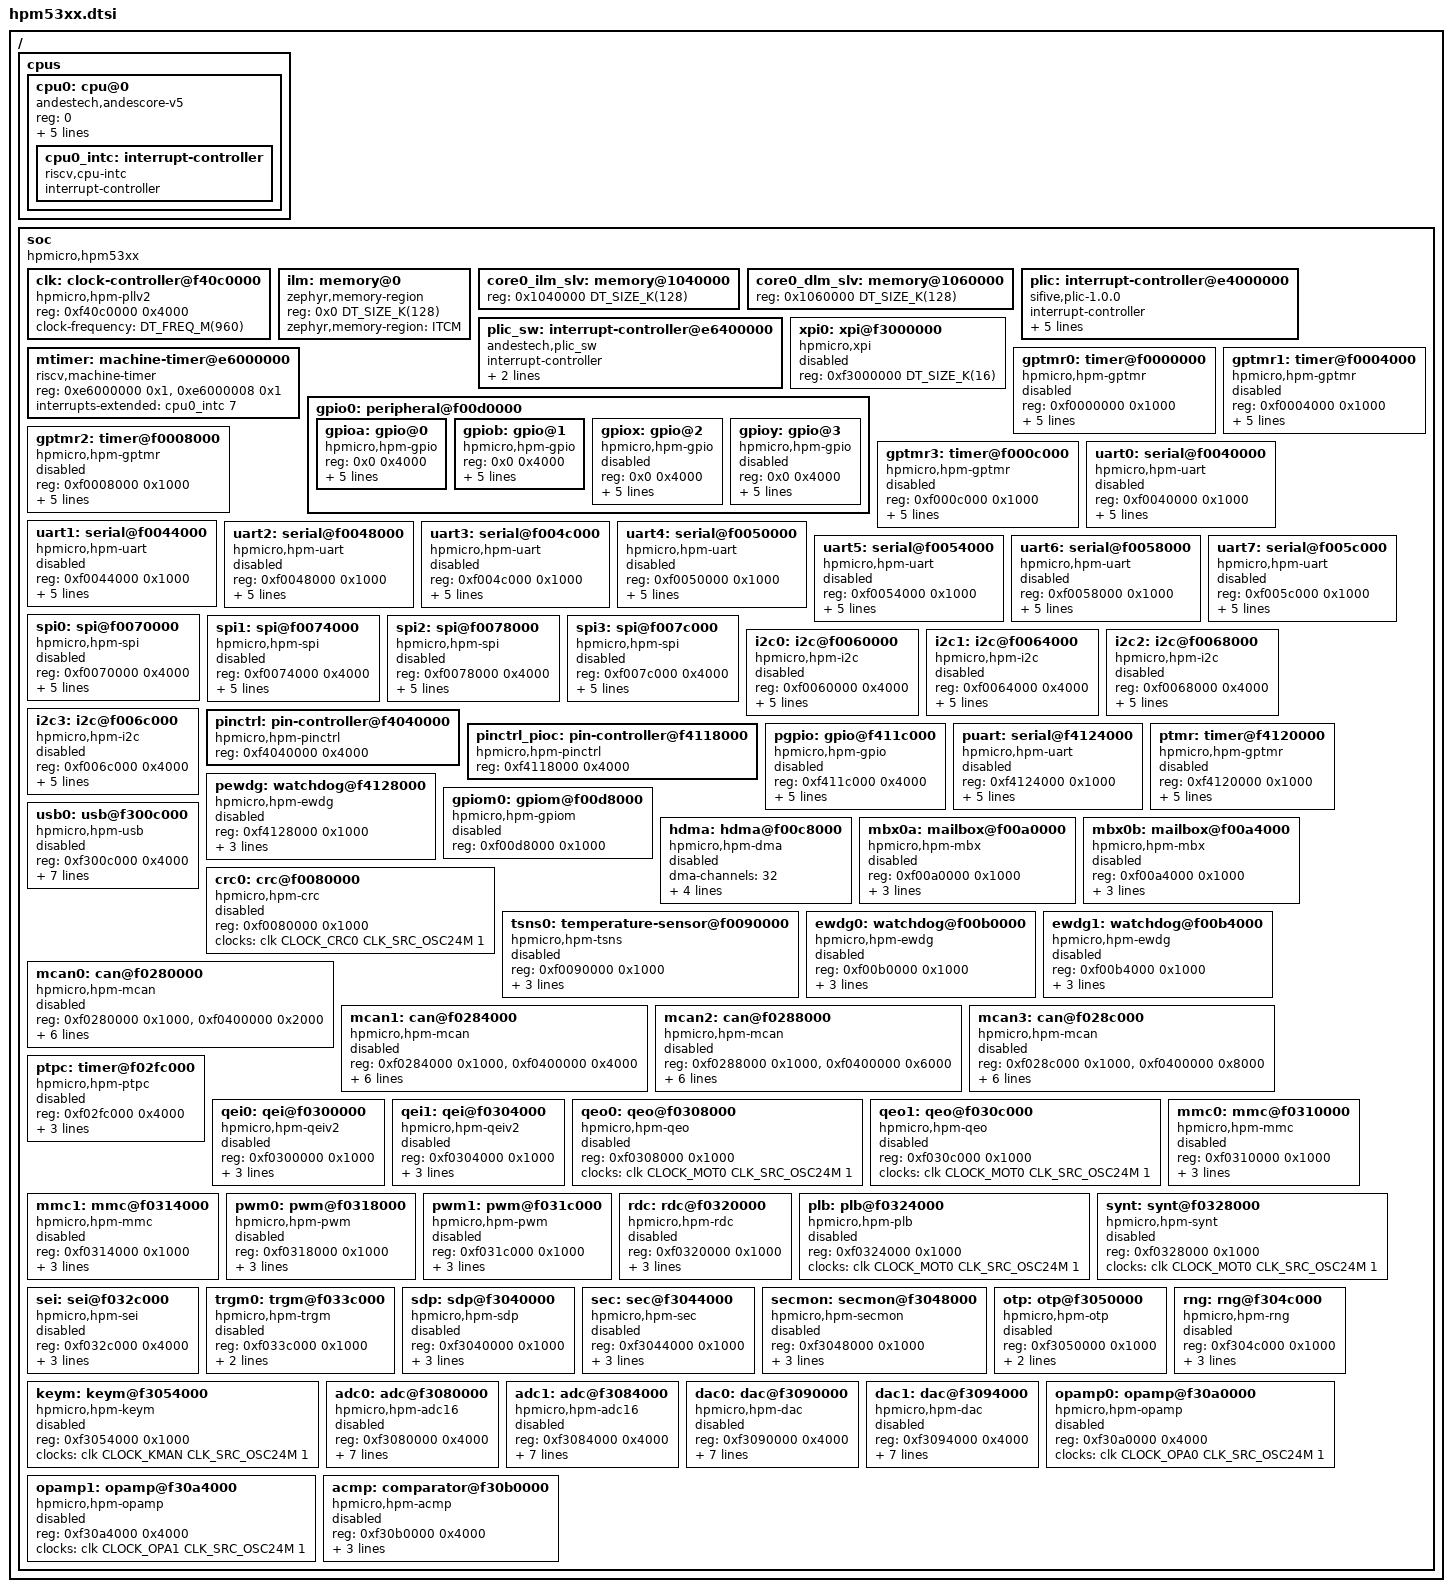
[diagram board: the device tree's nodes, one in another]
/*
 * Copyright (c) 2024-2026 HPMicro
 * SPDX-License-Identifier: Apache-2.0
 */

/dts-v1/;
#include <zephyr/dt-bindings/gpio/gpio.h>
#include <mem.h>
#include <freq.h>

/ {
	#address-cells = <1>;
	#size-cells = <1>;

	cpus {
		#address-cells = <1>;
		#size-cells = <0>;

		cpu0: cpu@0 {
			compatible = "andestech,andescore-v5", "riscv";
			reg = <0>;
			status = "okay";
			riscv,isa-base = "rv32i";
			riscv,isa-extensions = "i", "m", "a", "c", "zicsr", "zifencei";
			i-cache-line-size = <32>;
			d-cache-line-size = <32>;

			cpu0_intc: interrupt-controller {
				compatible = "riscv,cpu-intc";
				#address-cells = <0>;
				#interrupt-cells = <1>;
				interrupt-controller;
			};
		};
	};

	soc {
		#address-cells = <1>;
		#size-cells = <1>;
		compatible = "hpmicro,hpm53xx";
		ranges;

		clk: clock-controller@f40c0000 {
			compatible = "hpmicro,hpm-pllv2";
			reg = <0xf40c0000 0x4000>;
			clock-frequency = <DT_FREQ_M(960)>;
			reg-names = "clk";
			#clock-cells = <3>;
			status = "okay";
		};

		ilm: memory@0 {
			compatible = "zephyr,memory-region";
			reg = <0x0 DT_SIZE_K(128)>;
			zephyr,memory-region = "ITCM";
		};

		core0_ilm_slv: memory@1040000 {
			reg = <0x1040000 DT_SIZE_K(128)>;
		};

		core0_dlm_slv: memory@1060000 {
			reg = <0x1060000 DT_SIZE_K(128)>;
		};

		plic: interrupt-controller@e4000000 {
			compatible = "sifive,plic-1.0.0";
			#address-cells = <1>;
			#interrupt-cells = <2>;
			interrupt-controller;
			reg = <0xe4000000 0x1000>,
			      <0xe4002000 0x800>,
			      <0xe4200000 0x10000>;
			reg-names = "prio", "irq_en", "reg";
			riscv,max-priority = <31>;
			riscv,ndev = <127>;
			interrupts-extended = <&cpu0_intc 11>;
		};

		plic_sw: interrupt-controller@e6400000 {
			compatible = "andestech,plic_sw";
			#address-cells = <1>;
			#interrupt-cells = <2>;
			interrupt-controller;
			reg = <0xe6400000 0x400000>;
			interrupts-extended = <&cpu0_intc 3>;
		};

		mtimer: machine-timer@e6000000 {
			compatible = "riscv,machine-timer";
			reg = <0xe6000000 0x1>,
			      <0xe6000008 0x1>;
			reg-names = "mtime", "mtimecmp";
			interrupts-extended = <&cpu0_intc 7>;
		};

		xpi0: xpi@f3000000 {
			compatible = "hpmicro,xpi";
			reg = <0xf3000000 DT_SIZE_K(16)>;
			#address-cells = <1>;
			#size-cells = <1>;
			status = "disabled";
		};

		gpio0: peripheral@f00d0000 {
			#address-cells = <1>;
			#size-cells = <1>;
			ranges = <0x0 0xf00d0000 DT_SIZE_K(16)>;
		};

		gptmr0: timer@f0000000 {
			compatible = "hpmicro,hpm-gptmr";
			reg = <0xf0000000 0x1000>;
			interrupts = <5 1>;
			interrupt-parent = <&plic>;
			clocks = <&clk CLOCK_GPTMR0 CLK_SRC_OSC24M 1>;
			clock-names = "gptmr";
			clock-name = <CLOCK_GPTMR0>;
			clock-src = <CLK_SRC_OSC24M>;
			status = "disabled";
		};

		gptmr1: timer@f0004000 {
			compatible = "hpmicro,hpm-gptmr";
			reg = <0xf0004000 0x1000>;
			interrupts = <6 1>;
			interrupt-parent = <&plic>;
			clocks = <&clk CLOCK_GPTMR1 CLK_SRC_OSC24M 1>;
			clock-names = "gptmr";
			clock-name = <CLOCK_GPTMR1>;
			clock-src = <CLK_SRC_OSC24M>;
			status = "disabled";
		};

		gptmr2: timer@f0008000 {
			compatible = "hpmicro,hpm-gptmr";
			reg = <0xf0008000 0x1000>;
			interrupts = <7 1>;
			interrupt-parent = <&plic>;
			clocks = <&clk CLOCK_GPTMR2 CLK_SRC_OSC24M 1>;
			clock-names = "gptmr";
			clock-name = <CLOCK_GPTMR2>;
			clock-src = <CLK_SRC_OSC24M>;
			status = "disabled";
		};

		gptmr3: timer@f000c000 {
			compatible = "hpmicro,hpm-gptmr";
			reg = <0xf000c000 0x1000>;
			interrupts = <8 1>;
			interrupt-parent = <&plic>;
			clocks = <&clk CLOCK_GPTMR3 CLK_SRC_OSC24M 1>;
			clock-names = "gptmr";
			clock-name = <CLOCK_GPTMR3>;
			clock-src = <CLK_SRC_OSC24M>;
			status = "disabled";
		};

		uart0: serial@f0040000 {
			compatible = "hpmicro,hpm-uart";
			reg = <0xf0040000 0x1000>;
			interrupts = <13 1>;
			interrupt-names = "uart";
			clocks = <&clk CLOCK_UART0 CLK_SRC_OSC24M 1>;
			clock-names = "uart";
			clock-name = <CLOCK_UART0>;
			clock-src = <CLK_SRC_OSC24M>;
			interrupt-parent = <&plic>;
			status = "disabled";
		};

		uart1: serial@f0044000 {
			compatible = "hpmicro,hpm-uart";
			reg = <0xf0044000 0x1000>;
			interrupts = <14 1>;
			interrupt-names = "uart";
			clocks = <&clk CLOCK_UART1 CLK_SRC_OSC24M 1>;
			clock-names = "uart";
			clock-name = <CLOCK_UART1>;
			clock-src = <CLK_SRC_OSC24M>;
			interrupt-parent = <&plic>;
			status = "disabled";
		};

		uart2: serial@f0048000 {
			compatible = "hpmicro,hpm-uart";
			reg = <0xf0048000 0x1000>;
			interrupts = <15 1>;
			interrupt-names = "uart";
			clocks = <&clk CLOCK_UART2 CLK_SRC_OSC24M 1>;
			clock-names = "uart";
			clock-name = <CLOCK_UART2>;
			clock-src = <CLK_SRC_OSC24M>;
			interrupt-parent = <&plic>;
			status = "disabled";
		};

		uart3: serial@f004c000 {
			compatible = "hpmicro,hpm-uart";
			reg = <0xf004c000 0x1000>;
			interrupts = <16 1>;
			interrupt-names = "uart";
			clocks = <&clk CLOCK_UART3 CLK_SRC_OSC24M 1>;
			clock-names = "uart";
			clock-name = <CLOCK_UART3>;
			clock-src = <CLK_SRC_OSC24M>;
			interrupt-parent = <&plic>;
			status = "disabled";
		};

		uart4: serial@f0050000 {
			compatible = "hpmicro,hpm-uart";
			reg = <0xf0050000 0x1000>;
			interrupts = <17 1>;
			interrupt-names = "uart";
			clocks = <&clk CLOCK_UART4 CLK_SRC_OSC24M 1>;
			clock-names = "uart";
			clock-name = <CLOCK_UART4>;
			clock-src = <CLK_SRC_OSC24M>;
			interrupt-parent = <&plic>;
			status = "disabled";
		};

		uart5: serial@f0054000 {
			compatible = "hpmicro,hpm-uart";
			reg = <0xf0054000 0x1000>;
			interrupts = <18 1>;
			interrupt-names = "uart";
			clocks = <&clk CLOCK_UART5 CLK_SRC_OSC24M 1>;
			clock-names = "uart";
			clock-name = <CLOCK_UART5>;
			clock-src = <CLK_SRC_OSC24M>;
			interrupt-parent = <&plic>;
			status = "disabled";
		};

		uart6: serial@f0058000 {
			compatible = "hpmicro,hpm-uart";
			reg = <0xf0058000 0x1000>;
			interrupts = <19 1>;
			interrupt-names = "uart";
			clocks = <&clk CLOCK_UART6 CLK_SRC_OSC24M 1>;
			clock-names = "uart";
			clock-name = <CLOCK_UART6>;
			clock-src = <CLK_SRC_OSC24M>;
			interrupt-parent = <&plic>;
			status = "disabled";
		};

		uart7: serial@f005c000 {
			compatible = "hpmicro,hpm-uart";
			reg = <0xf005c000 0x1000>;
			interrupts = <20 1>;
			interrupt-names = "uart";
			clocks = <&clk CLOCK_UART7 CLK_SRC_OSC24M 1>;
			clock-names = "uart";
			clock-name = <CLOCK_UART7>;
			clock-src = <CLK_SRC_OSC24M>;
			interrupt-parent = <&plic>;
			status = "disabled";
		};

		spi0: spi@f0070000 {
			compatible = "hpmicro,hpm-spi";
			reg = <0xf0070000 0x4000>;
			interrupts = <25 1>;
			interrupt-parent = <&plic>;
			clocks = <&clk CLOCK_SPI0 CLK_SRC_PLL1_CLK0 10>;
			clock-names = "spi";
			clock-name = <CLOCK_SPI0>;
			clock-src = <CLK_SRC_PLL1_CLK0>;
			#address-cells = <1>;
			#size-cells = <0>;
			status = "disabled";
		};

		spi1: spi@f0074000 {
			compatible = "hpmicro,hpm-spi";
			reg = <0xf0074000 0x4000>;
			interrupts = <26 1>;
			interrupt-parent = <&plic>;
			clocks = <&clk CLOCK_SPI1 CLK_SRC_PLL1_CLK0 10>;
			clock-names = "spi";
			clock-name = <CLOCK_SPI1>;
			clock-src = <CLK_SRC_PLL1_CLK0>;
			#address-cells = <1>;
			#size-cells = <0>;
			status = "disabled";
		};

		spi2: spi@f0078000 {
			compatible = "hpmicro,hpm-spi";
			reg = <0xf0078000 0x4000>;
			interrupts = <27 1>;
			interrupt-parent = <&plic>;
			clocks = <&clk CLOCK_SPI2 CLK_SRC_PLL1_CLK0 10>;
			clock-names = "spi";
			clock-name = <CLOCK_SPI2>;
			clock-src = <CLK_SRC_PLL1_CLK0>;
			#address-cells = <1>;
			#size-cells = <0>;
			status = "disabled";
		};

		spi3: spi@f007c000 {
			compatible = "hpmicro,hpm-spi";
			reg = <0xf007c000 0x4000>;
			interrupts = <28 1>;
			interrupt-parent = <&plic>;
			clocks = <&clk CLOCK_SPI3 CLK_SRC_PLL1_CLK0 10>;
			clock-names = "spi";
			clock-name = <CLOCK_SPI3>;
			clock-src = <CLK_SRC_PLL1_CLK0>;
			#address-cells = <1>;
			#size-cells = <0>;
			status = "disabled";
		};

		i2c0: i2c@f0060000 {
			compatible = "hpmicro,hpm-i2c";
			reg = <0xf0060000 0x4000>;
			interrupts = <21 1>;
			interrupt-parent = <&plic>;
			clocks = <&clk CLOCK_I2C0 CLK_SRC_PLL1_CLK0 10>;
			clock-names = "i2c";
			clock-name = <CLOCK_I2C0>;
			clock-src = <CLK_SRC_PLL1_CLK0>;
			#address-cells = <1>;
			#size-cells = <0>;
			status = "disabled";
		};

		i2c1: i2c@f0064000 {
			compatible = "hpmicro,hpm-i2c";
			reg = <0xf0064000 0x4000>;
			interrupts = <22 1>;
			interrupt-parent = <&plic>;
			clocks = <&clk CLOCK_I2C1 CLK_SRC_PLL1_CLK0 10>;
			clock-names = "i2c";
			clock-name = <CLOCK_I2C1>;
			clock-src = <CLK_SRC_PLL1_CLK0>;
			#address-cells = <1>;
			#size-cells = <0>;
			status = "disabled";
		};

		i2c2: i2c@f0068000 {
			compatible = "hpmicro,hpm-i2c";
			reg = <0xf0068000 0x4000>;
			interrupts = <23 1>;
			interrupt-parent = <&plic>;
			clocks = <&clk CLOCK_I2C2 CLK_SRC_PLL1_CLK0 10>;
			clock-names = "i2c";
			clock-name = <CLOCK_I2C2>;
			clock-src = <CLK_SRC_PLL1_CLK0>;
			#address-cells = <1>;
			#size-cells = <0>;
			status = "disabled";
		};

		i2c3: i2c@f006c000 {
			compatible = "hpmicro,hpm-i2c";
			reg = <0xf006c000 0x4000>;
			interrupts = <24 1>;
			interrupt-parent = <&plic>;
			clocks = <&clk CLOCK_I2C3 CLK_SRC_PLL1_CLK0 10>;
			clock-names = "i2c";
			clock-name = <CLOCK_I2C3>;
			clock-src = <CLK_SRC_PLL1_CLK0>;
			#address-cells = <1>;
			#size-cells = <0>;
			status = "disabled";
		};

		pinctrl: pin-controller@f4040000 {
			compatible = "hpmicro,hpm-pinctrl";
			reg = <0xf4040000 0x4000>;
			status = "okay";
		};

		pinctrl_pioc: pin-controller@f4118000 {
			compatible = "hpmicro,hpm-pinctrl";
			reg = <0xf4118000 0x4000>;
			status = "okay";
		};

		pgpio: gpio@f411c000 {
			compatible = "hpmicro,hpm-gpio";
			reg = <0xf411c000 0x4000>;
			ngpios = <8>;
			gpio-controller;
			#gpio-cells = <2>;
			hpmicro-gpio-port = <0>;
			interrupts = <65 1>;
			interrupt-parent = <&plic>;
			status = "disabled";
		};

		puart: serial@f4124000 {
			compatible = "hpmicro,hpm-uart";
			reg = <0xf4124000 0x1000>;
			interrupts = <67 1>;
			interrupt-names = "uart";
			interrupt-parent = <&plic>;
			clocks = <&clk CLOCK_PUART CLK_SRC_OSC24M 1>;
			clock-names = "uart";
			clock-name = <CLOCK_PUART>;
			clock-src = <CLK_SRC_OSC24M>;
			status = "disabled";
		};

		ptmr: timer@f4120000 {
			compatible = "hpmicro,hpm-gptmr";
			reg = <0xf4120000 0x1000>;
			interrupts = <66 1>;
			interrupt-parent = <&plic>;
			clocks = <&clk CLOCK_PTMR CLK_SRC_OSC24M 1>;
			clock-names = "gptmr";
			clock-name = <CLOCK_PTMR>;
			clock-src = <CLK_SRC_OSC24M>;
			status = "disabled";
		};

		pewdg: watchdog@f4128000 {
			compatible = "hpmicro,hpm-ewdg";
			reg = <0xf4128000 0x1000>;
			interrupts = <68 1>;
			interrupt-parent = <&plic>;
			clocks = <&clk CLOCK_PWDG CLK_SRC_OSC24M 1>;
			clock-names = "ewdg";
			status = "disabled";
		};

		gpiom0: gpiom@f00d8000 {
			compatible = "hpmicro,hpm-gpiom";
			reg = <0xf00d8000 0x1000>;
			status = "disabled";
		};

		hdma: hdma@f00c8000 {
			#dma-cells = <2>;
			compatible = "hpmicro,hpm-dma";
			dma-channels = <32>;
			dma-requests = <32>;
			reg = <0xf00c8000 0x4000>,
			      <0xf00c4000 0x4000>;
			interrupts = <34 1>;
			interrupt-parent = <&plic>;
			status = "disabled";
		};

		mbx0a: mailbox@f00a0000 {
			compatible = "hpmicro,hpm-mbx";
			reg = <0xf00a0000 0x1000>;
			interrupts = <30 1>;
			interrupt-parent = <&plic>;
			clocks = <&clk CLOCK_MBX0 CLK_SRC_OSC24M 1>;
			clock-names = "mbx";
			status = "disabled";
		};

		mbx0b: mailbox@f00a4000 {
			compatible = "hpmicro,hpm-mbx";
			reg = <0xf00a4000 0x1000>;
			interrupts = <31 1>;
			interrupt-parent = <&plic>;
			clocks = <&clk CLOCK_MBX0 CLK_SRC_OSC24M 1>;
			clock-names = "mbx";
			status = "disabled";
		};

		usb0: usb@f300c000 {
			compatible = "hpmicro,hpm-usb";
			reg = <0xf300c000 0x4000>;
			interrupts = <51 1>;
			interrupt-parent = <&plic>;
			clocks = <&clk CLOCK_USB0 CLK_SRC_OSC24M 1>;
			clock-names = "usb";
			clock-name = <CLOCK_USB0>;
			clock-src = <CLK_SRC_OSC24M>;
			maximum-speed = "high-speed";
			num-bidir-endpoints = <16>;
			status = "disabled";
		};

		crc0: crc@f0080000 {
			compatible = "hpmicro,hpm-crc";
			reg = <0xf0080000 0x1000>;
			clocks = <&clk CLOCK_CRC0 CLK_SRC_OSC24M 1>;
			clock-names = "crc";
			status = "disabled";
		};

		tsns0: temperature-sensor@f0090000 {
			compatible = "hpmicro,hpm-tsns";
			reg = <0xf0090000 0x1000>;
			interrupts = <29 1>;
			interrupt-parent = <&plic>;
			clocks = <&clk CLOCK_TSNS CLK_SRC_OSC24M 1>;
			clock-names = "tsns";
			status = "disabled";
		};

		ewdg0: watchdog@f00b0000 {
			compatible = "hpmicro,hpm-ewdg";
			reg = <0xf00b0000 0x1000>;
			interrupts = <32 1>;
			interrupt-parent = <&plic>;
			clocks = <&clk CLOCK_WATCHDOG0 CLK_SRC_OSC24M 1>;
			clock-names = "ewdg";
			status = "disabled";
		};

		ewdg1: watchdog@f00b4000 {
			compatible = "hpmicro,hpm-ewdg";
			reg = <0xf00b4000 0x1000>;
			interrupts = <33 1>;
			interrupt-parent = <&plic>;
			clocks = <&clk CLOCK_WATCHDOG1 CLK_SRC_OSC24M 1>;
			clock-names = "ewdg";
			status = "disabled";
		};

		/*
		 * All MCAN instances share the 32 KiB AHB SRAM at 0xF0400000.
		 * Each instance owns an 8 KiB window selected by the offset in
		 * bosch,mram-cfg. The message_ram reg range ends at each instance's
		 * window, so the generic Bosch M_CAN frontend derives an exact 8 KiB
		 * MRAM size after applying the per-instance offset.
		 */
		mcan0: can@f0280000 {
			compatible = "hpmicro,hpm-mcan";
			reg = <0xf0280000 0x1000>,
			      <0xf0400000 0x2000>;
			reg-names = "m_can", "message_ram";
			interrupts = <35 1>;
			interrupt-parent = <&plic>;
			clocks = <&clk CLOCK_CAN0 CLK_SRC_PLL1_CLK0 10>;
			clock-names = "can";
			clock-name = <CLOCK_CAN0>;
			clock-src = <CLK_SRC_PLL1_CLK0>;
			bosch,mram-cfg = <0x0 14 8 8 0 0 4 8>;
			status = "disabled";
		};

		mcan1: can@f0284000 {
			compatible = "hpmicro,hpm-mcan";
			reg = <0xf0284000 0x1000>,
			      <0xf0400000 0x4000>;
			reg-names = "m_can", "message_ram";
			interrupts = <36 1>;
			interrupt-parent = <&plic>;
			clocks = <&clk CLOCK_CAN1 CLK_SRC_PLL1_CLK0 10>;
			clock-names = "can";
			clock-name = <CLOCK_CAN1>;
			clock-src = <CLK_SRC_PLL1_CLK0>;
			bosch,mram-cfg = <0x2000 14 8 8 0 0 4 8>;
			status = "disabled";
		};

		mcan2: can@f0288000 {
			compatible = "hpmicro,hpm-mcan";
			reg = <0xf0288000 0x1000>,
			      <0xf0400000 0x6000>;
			reg-names = "m_can", "message_ram";
			interrupts = <37 1>;
			interrupt-parent = <&plic>;
			clocks = <&clk CLOCK_CAN2 CLK_SRC_PLL1_CLK0 10>;
			clock-names = "can";
			clock-name = <CLOCK_CAN2>;
			clock-src = <CLK_SRC_PLL1_CLK0>;
			bosch,mram-cfg = <0x4000 14 8 8 0 0 4 8>;
			status = "disabled";
		};

		mcan3: can@f028c000 {
			compatible = "hpmicro,hpm-mcan";
			reg = <0xf028c000 0x1000>,
			      <0xf0400000 0x8000>;
			reg-names = "m_can", "message_ram";
			interrupts = <38 1>;
			interrupt-parent = <&plic>;
			clocks = <&clk CLOCK_CAN3 CLK_SRC_PLL1_CLK0 10>;
			clock-names = "can";
			clock-name = <CLOCK_CAN3>;
			clock-src = <CLK_SRC_PLL1_CLK0>;
			bosch,mram-cfg = <0x6000 14 8 8 0 0 4 8>;
			status = "disabled";
		};

		ptpc: timer@f02fc000 {
			compatible = "hpmicro,hpm-ptpc";
			reg = <0xf02fc000 0x4000>;
			interrupts = <39 1>;
			interrupt-parent = <&plic>;
			clocks = <&clk CLOCK_PTPC CLK_SRC_OSC24M 1>;
			clock-names = "ptpc";
			status = "disabled";
		};

		qei0: qei@f0300000 {
			compatible = "hpmicro,hpm-qeiv2";
			reg = <0xf0300000 0x1000>;
			interrupts = <41 1>;
			interrupt-parent = <&plic>;
			clocks = <&clk CLOCK_MOT0 CLK_SRC_OSC24M 1>;
			clock-names = "qei";
			status = "disabled";
		};

		qei1: qei@f0304000 {
			compatible = "hpmicro,hpm-qeiv2";
			reg = <0xf0304000 0x1000>;
			interrupts = <46 1>;
			interrupt-parent = <&plic>;
			clocks = <&clk CLOCK_MOT0 CLK_SRC_OSC24M 1>;
			clock-names = "qei";
			status = "disabled";
		};

		qeo0: qeo@f0308000 {
			compatible = "hpmicro,hpm-qeo";
			reg = <0xf0308000 0x1000>;
			clocks = <&clk CLOCK_MOT0 CLK_SRC_OSC24M 1>;
			clock-names = "qeo";
			status = "disabled";
		};

		qeo1: qeo@f030c000 {
			compatible = "hpmicro,hpm-qeo";
			reg = <0xf030c000 0x1000>;
			clocks = <&clk CLOCK_MOT0 CLK_SRC_OSC24M 1>;
			clock-names = "qeo";
			status = "disabled";
		};

		mmc0: mmc@f0310000 {
			compatible = "hpmicro,hpm-mmc";
			reg = <0xf0310000 0x1000>;
			interrupts = <43 1>;
			interrupt-parent = <&plic>;
			clocks = <&clk CLOCK_MOT0 CLK_SRC_OSC24M 1>;
			clock-names = "mmc";
			status = "disabled";
		};

		mmc1: mmc@f0314000 {
			compatible = "hpmicro,hpm-mmc";
			reg = <0xf0314000 0x1000>;
			interrupts = <48 1>;
			interrupt-parent = <&plic>;
			clocks = <&clk CLOCK_MOT0 CLK_SRC_OSC24M 1>;
			clock-names = "mmc";
			status = "disabled";
		};

		pwm0: pwm@f0318000 {
			compatible = "hpmicro,hpm-pwm";
			reg = <0xf0318000 0x1000>;
			interrupts = <40 1>;
			interrupt-parent = <&plic>;
			clocks = <&clk CLOCK_MOT0 CLK_SRC_OSC24M 1>;
			clock-names = "pwm";
			#pwm-cells = <3>;
			status = "disabled";
		};

		pwm1: pwm@f031c000 {
			compatible = "hpmicro,hpm-pwm";
			reg = <0xf031c000 0x1000>;
			interrupts = <45 1>;
			interrupt-parent = <&plic>;
			clocks = <&clk CLOCK_MOT0 CLK_SRC_OSC24M 1>;
			clock-names = "pwm";
			#pwm-cells = <3>;
			status = "disabled";
		};

		rdc: rdc@f0320000 {
			compatible = "hpmicro,hpm-rdc";
			reg = <0xf0320000 0x1000>;
			interrupts = <50 1>;
			interrupt-parent = <&plic>;
			clocks = <&clk CLOCK_MOT0 CLK_SRC_OSC24M 1>;
			clock-names = "rdc";
			status = "disabled";
		};

		plb: plb@f0324000 {
			compatible = "hpmicro,hpm-plb";
			reg = <0xf0324000 0x1000>;
			clocks = <&clk CLOCK_MOT0 CLK_SRC_OSC24M 1>;
			clock-names = "plb";
			status = "disabled";
		};

		synt: synt@f0328000 {
			compatible = "hpmicro,hpm-synt";
			reg = <0xf0328000 0x1000>;
			clocks = <&clk CLOCK_MOT0 CLK_SRC_OSC24M 1>;
			clock-names = "synt";
			status = "disabled";
		};

		sei: sei@f032c000 {
			compatible = "hpmicro,hpm-sei";
			reg = <0xf032c000 0x4000>;
			interrupts = <42 1>, <47 1>;
			interrupt-parent = <&plic>;
			clocks = <&clk CLOCK_MOT0 CLK_SRC_OSC24M 1>;
			clock-names = "sei";
			status = "disabled";
		};

		trgm0: trgm@f033c000 {
			compatible = "hpmicro,hpm-trgm";
			reg = <0xf033c000 0x1000>;
			interrupts = <44 1>, <49 1>;
			interrupt-parent = <&plic>;
			status = "disabled";
		};

		sdp: sdp@f3040000 {
			compatible = "hpmicro,hpm-sdp";
			reg = <0xf3040000 0x1000>;
			interrupts = <53 1>;
			interrupt-parent = <&plic>;
			clocks = <&clk CLOCK_SDP CLK_SRC_OSC24M 1>;
			clock-names = "sdp";
			status = "disabled";
		};

		sec: sec@f3044000 {
			compatible = "hpmicro,hpm-sec";
			reg = <0xf3044000 0x1000>;
			interrupts = <54 1>;
			interrupt-parent = <&plic>;
			clocks = <&clk CLOCK_SDP CLK_SRC_OSC24M 1>;
			clock-names = "sec";
			status = "disabled";
		};

		secmon: secmon@f3048000 {
			compatible = "hpmicro,hpm-secmon";
			reg = <0xf3048000 0x1000>;
			interrupts = <55 1>;
			interrupt-parent = <&plic>;
			clocks = <&clk CLOCK_SDP CLK_SRC_OSC24M 1>;
			clock-names = "secmon";
			status = "disabled";
		};

		otp: otp@f3050000 {
			compatible = "hpmicro,hpm-otp";
			reg = <0xf3050000 0x1000>;
			interrupts = <57 1>;
			interrupt-parent = <&plic>;
			status = "disabled";
		};

		keym: keym@f3054000 {
			compatible = "hpmicro,hpm-keym";
			reg = <0xf3054000 0x1000>;
			clocks = <&clk CLOCK_KMAN CLK_SRC_OSC24M 1>;
			clock-names = "keym";
			status = "disabled";
		};

		rng: rng@f304c000 {
			compatible = "hpmicro,hpm-rng";
			reg = <0xf304c000 0x1000>;
			interrupts = <56 1>;
			interrupt-parent = <&plic>;
			clocks = <&clk CLOCK_RNG CLK_SRC_OSC24M 1>;
			clock-names = "rng";
			status = "disabled";
		};

		adc0: adc@f3080000 {
			compatible = "hpmicro,hpm-adc16";
			reg = <0xf3080000 0x4000>;
			interrupts = <58 1>;
			interrupt-parent = <&plic>;
			clocks = <&clk CLOCK_ADC0 CLK_SRC_PLL0_CLK2 2>;
			clock-names = "adc";
			clock-name = <CLOCK_ADC0>;
			clock-src = <CLK_ADC_SRC_ANA0>;
			ana-clock-name = <CLOCK_ANA0>;
			ana-clock-src = <CLK_SRC_PLL0_CLK2>;
			#io-channel-cells = <1>;
			status = "disabled";
		};

		adc1: adc@f3084000 {
			compatible = "hpmicro,hpm-adc16";
			reg = <0xf3084000 0x4000>;
			interrupts = <59 1>;
			interrupt-parent = <&plic>;
			clocks = <&clk CLOCK_ADC1 CLK_SRC_PLL0_CLK2 2>;
			clock-names = "adc";
			clock-name = <CLOCK_ADC1>;
			clock-src = <CLK_ADC_SRC_ANA1>;
			ana-clock-name = <CLOCK_ANA1>;
			ana-clock-src = <CLK_SRC_PLL0_CLK2>;
			#io-channel-cells = <1>;
			status = "disabled";
		};

		dac0: dac@f3090000 {
			compatible = "hpmicro,hpm-dac";
			reg = <0xf3090000 0x4000>;
			interrupts = <60 1>;
			interrupt-parent = <&plic>;
			clocks = <&clk CLOCK_DAC0 CLK_SRC_PLL1_CLK2 3>;
			clock-names = "dac";
			clock-name = <CLOCK_DAC0>;
			clock-src = <CLK_DAC_SRC_ANA2>;
			ana-clock-name = <CLOCK_ANA2>;
			ana-clock-src = <CLK_SRC_PLL1_CLK2>;
			#io-channel-cells = <1>;
			status = "disabled";
		};

		dac1: dac@f3094000 {
			compatible = "hpmicro,hpm-dac";
			reg = <0xf3094000 0x4000>;
			interrupts = <61 1>;
			interrupt-parent = <&plic>;
			clocks = <&clk CLOCK_DAC1 CLK_SRC_PLL1_CLK2 3>;
			clock-names = "dac";
			clock-name = <CLOCK_DAC1>;
			clock-src = <CLK_DAC_SRC_ANA3>;
			ana-clock-name = <CLOCK_ANA3>;
			ana-clock-src = <CLK_SRC_PLL1_CLK2>;
			#io-channel-cells = <1>;
			status = "disabled";
		};

		opamp0: opamp@f30a0000 {
			compatible = "hpmicro,hpm-opamp";
			reg = <0xf30a0000 0x4000>;
			clocks = <&clk CLOCK_OPA0 CLK_SRC_OSC24M 1>;
			clock-names = "opamp";
			status = "disabled";
		};

		opamp1: opamp@f30a4000 {
			compatible = "hpmicro,hpm-opamp";
			reg = <0xf30a4000 0x4000>;
			clocks = <&clk CLOCK_OPA1 CLK_SRC_OSC24M 1>;
			clock-names = "opamp";
			status = "disabled";
		};

		acmp: comparator@f30b0000 {
			compatible = "hpmicro,hpm-acmp";
			reg = <0xf30b0000 0x4000>;
			interrupts = <62 1>, <63 1>;
			interrupt-parent = <&plic>;
			clocks = <&clk CLOCK_ACMP0 CLK_SRC_OSC24M 1>;
			clock-names = "acmp";
			status = "disabled";
		};
	};
};

&gpio0 {
	/*
	 * All GPIO ports share the GPIO0 register block. The unit-address is
	 * only a unique node identifier; hpmicro-gpio-port selects the port.
	 */
	gpioa: gpio@0 {
		compatible = "hpmicro,hpm-gpio";
		reg = <0x0 0x4000>;
		ngpios = <32>;
		gpio-controller;
		#gpio-cells = <2>;
		hpmicro-gpio-port = <0>;
		interrupts = <1 1>;
		interrupt-parent = <&plic>;
	};

	gpiob: gpio@1 {
		compatible = "hpmicro,hpm-gpio";
		reg = <0x0 0x4000>;
		ngpios = <32>;
		gpio-controller;
		#gpio-cells = <2>;
		hpmicro-gpio-port = <1>;
		interrupts = <2 1>;
		interrupt-parent = <&plic>;
	};

	gpiox: gpio@2 {
		compatible = "hpmicro,hpm-gpio";
		reg = <0x0 0x4000>;
		ngpios = <8>;
		gpio-controller;
		#gpio-cells = <2>;
		hpmicro-gpio-port = <13>;
		interrupts = <3 1>;
		interrupt-parent = <&plic>;
		status = "disabled";
	};

	gpioy: gpio@3 {
		compatible = "hpmicro,hpm-gpio";
		reg = <0x0 0x4000>;
		ngpios = <8>;
		gpio-controller;
		#gpio-cells = <2>;
		hpmicro-gpio-port = <14>;
		interrupts = <4 1>;
		interrupt-parent = <&plic>;
		status = "disabled";
	};
};
